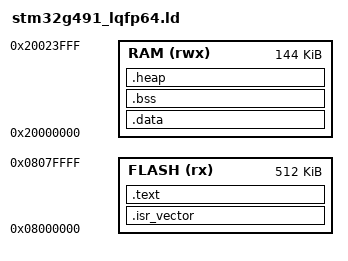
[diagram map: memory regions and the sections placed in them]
/*
 * stm32g491_lqfp64.ld — linker script for STM32G491RET6 (LQFP64)
 * 512 KB flash, 144 KB SRAM.
 */
ENTRY(Reset_Handler)

MEMORY
{
    FLASH (rx)  : ORIGIN = 0x08000000, LENGTH = 512K
    RAM   (rwx) : ORIGIN = 0x20000000, LENGTH = 144K
}

_estack = ORIGIN(RAM) + LENGTH(RAM);

SECTIONS
{
    .isr_vector :
    {
        . = ALIGN(4);
        KEEP(*(.isr_vector))
        . = ALIGN(4);
    } > FLASH

    .text :
    {
        . = ALIGN(4);
        *(.text)
        *(.text*)
        *(.rodata)
        *(.rodata*)
        . = ALIGN(4);
        _etext = .;
    } > FLASH

    .data : AT (_etext)
    {
        . = ALIGN(4);
        _sdata = .;
        *(.data)
        *(.data*)
        . = ALIGN(4);
        _edata = .;
    } > RAM

    .bss :
    {
        . = ALIGN(4);
        _sbss = .;
        *(.bss)
        *(.bss*)
        *(COMMON)
        . = ALIGN(4);
        _ebss = .;
    } > RAM

    .heap :
    {
        . = ALIGN(8);
        _sheap = .;
        . = . + 0x1000;
        _eheap = .;
    } > RAM

    _sstack = ORIGIN(RAM);
    _estack_top = ORIGIN(RAM) + LENGTH(RAM);
}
